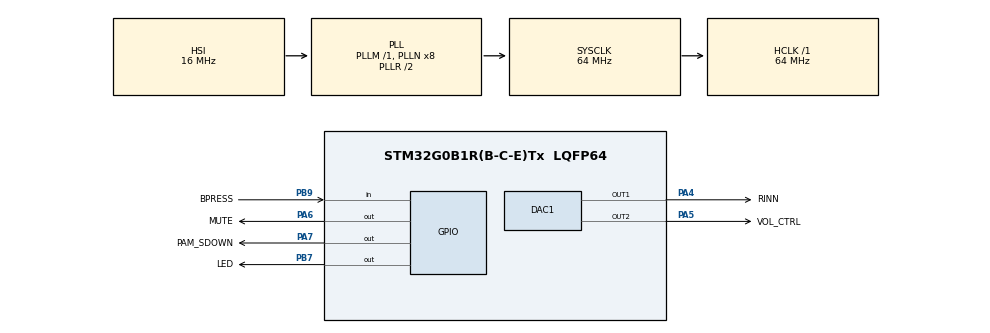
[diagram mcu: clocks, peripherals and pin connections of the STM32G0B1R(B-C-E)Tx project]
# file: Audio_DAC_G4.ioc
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DAC1.DAC_Channel-DAC_OUT1=DAC_CHANNEL_1
DAC1.DAC_Channel-DAC_OUT2=DAC_CHANNEL_2
DAC1.DAC_Trigger-DAC_OUT1=DAC_TRIGGER_T15_TRGO
Dma.DAC1_CH1.0.Direction=DMA_MEMORY_TO_PERIPH
Dma.DAC1_CH1.0.EventEnable=DISABLE
Dma.DAC1_CH1.0.Instance=DMA1_Channel1
Dma.DAC1_CH1.0.MemDataAlignment=DMA_MDATAALIGN_HALFWORD
Dma.DAC1_CH1.0.MemInc=DMA_MINC_ENABLE
Dma.DAC1_CH1.0.Mode=DMA_NORMAL
Dma.DAC1_CH1.0.PeriphDataAlignment=DMA_PDATAALIGN_HALFWORD
Dma.DAC1_CH1.0.PeriphInc=DMA_PINC_DISABLE
Dma.DAC1_CH1.0.Polarity=HAL_DMAMUX_REQ_GEN_RISING
Dma.DAC1_CH1.0.Priority=DMA_PRIORITY_LOW
Dma.DAC1_CH1.0.RequestNumber=1
Dma.DAC1_CH1.0.SignalID=NONE
Dma.DAC1_CH1.0.SyncEnable=DISABLE
Dma.DAC1_CH1.0.SyncPolarity=HAL_DMAMUX_SYNC_NO_EVENT
Dma.DAC1_CH1.0.SyncRequestNumber=1
Dma.DAC1_CH1.0.SyncSignalID=NONE
Dma.Request0=DAC1_CH1
Mcu.Family=STM32G0
Mcu.Name=STM32G0B1R(B-C-E)Tx
Mcu.Package=LQFP64
NVIC.DMA1_Channel1_IRQn=true\:0\:0\:false\:false\:true\:false\:true\:true
NVIC.TIM6_DAC_LPTIM1_IRQn=true\:0\:0\:false\:false\:true\:true\:true\:true
PA13.Mode=Serial_Wire
PA13.Signal=SYS_SWDIO
PA14-BOOT0.Mode=Serial_Wire
PA14-BOOT0.Signal=SYS_SWCLK
PA4.GPIO_Label=RINN
PA4.Signal=COMP_DAC11_group
PA5.GPIO_Label=VOL_CTRL
PA5.Signal=COMP_DAC12_group
PA6.GPIO_Label=MUTE
PA6.Signal=GPIO_Output
PA7.GPIO_Label=PAM_SDOWN
PA7.Signal=GPIO_Output
PB7.GPIO_Label=LED
PB7.Signal=GPIO_Output
PB9.GPIO_Label=BPRESS
PB9.Signal=GPIO_Input
ProjectManager.HeapSize=0x200
ProjectManager.StackSize=0x400
ProjectManager.TargetToolchain=STM32CubeIDE
RCC.ADCFreq_Value=64000000
RCC.AHBFreq_Value=64000000
RCC.CortexFreq_Value=64000000
RCC.EXTERNAL_CLOCK_VALUE=12288000
RCC.HCLKFreq_Value=64000000
RCC.HSE_VALUE=8000000
RCC.HSI48_VALUE=48000000
RCC.HSI_VALUE=16000000
RCC.LSE_VALUE=32768
RCC.PLLQ=RCC_PLLQ_DIV4
RCC.SYSCLKFreq_VALUE=64000000
RCC.SYSCLKSource=RCC_SYSCLKSOURCE_PLLCLK
RCC.USBFreq_Value=48000000
RCC.VCOOutputFreq_Value=128000000
SH.COMP_DAC11_group.0=DAC1_OUT1,DAC_OUT1
SH.COMP_DAC12_group.0=DAC1_OUT2,DAC_OUT2
TIM15.Period=3999
TIM15.Prescaler=1
TIM15.TIM_MasterOutputTrigger=TIM_TRGO_UPDATE
VP_SYS_VS_DBSignals.Mode=DisableDeadBatterySignals
VP_TIM15_VS_ClockSourceINT.Mode=Internal
board=NUCLEO-G0B1RE

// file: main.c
/* USER CODE BEGIN Header */
/**
  ******************************************************************************
  * @file           : main.c
  * @brief          : Main program body
  ******************************************************************************
  * @attention
  *
  * Copyright (c) 2024 STMicroelectronics.
  * All rights reserved.
  *
  * This software is licensed under terms that can be found in the LICENSE file
  * in the root directory of this software component.
  * If no LICENSE file comes with this software, it is provided AS-IS.
  *
  ******************************************************************************
  */
/* USER CODE END Header */
#include "main.h"

/* USER CODE BEGIN Includes */
#include "audio.h"

/* USER CODE END Includes */

DAC_HandleTypeDef hdac1;
DMA_HandleTypeDef hdma_dac1_ch1;

TIM_HandleTypeDef htim15;

/* USER CODE BEGIN PV */

uint32_t volume = 4000; //0=max e 4095=min
/* USER CODE END PV */

void SystemClock_Config(void);
static void MX_GPIO_Init(void);
static void MX_DMA_Init(void);
static void MX_DAC1_Init(void);
static void MX_TIM15_Init(void);

int main(void)
{

  /* MCU Configuration--------------------------------------------------------*/

  /* Reset of all peripherals, Initializes the Flash interface and the Systick. */
  HAL_Init();

  /* Configure the system clock */
  SystemClock_Config();

  /* Initialize all configured peripherals */
  MX_GPIO_Init();
  MX_DMA_Init();
  MX_DAC1_Init();
  MX_TIM15_Init();
  /* USER CODE BEGIN 2 */

  HAL_TIM_Base_Start(&htim15); 		//Audio control timer for 8kHz/125us
  HAL_DAC_Start(&hdac1, DAC_CHANNEL_2); 		//Start DAC volume control
  HAL_DAC_SetValue(&hdac1, DAC_CHANNEL_2, DAC_ALIGN_12B_R, volume);

  HAL_GPIO_WritePin(GPIOA, PAM_SDOWN_Pin, GPIO_PIN_SET); //Full Chip ShutDown Active Low
  HAL_GPIO_WritePin(MUTE_GPIO_Port, MUTE_Pin, GPIO_PIN_RESET);
  /* USER CODE END 2 */

  /* Infinite loop */
  /* USER CODE BEGIN WHILE */
  while (1)
  {
	  if (!HAL_GPIO_ReadPin(BPRESS_GPIO_Port, BPRESS_Pin))
	  {

		  HAL_DAC_SetValue(&hdac1, DAC_CHANNEL_2, DAC_ALIGN_12B_R, volume);
		  HAL_DAC_Start_DMA(&hdac1, DAC_CHANNEL_1, (uint32_t*)arq_audio, tam_total, DAC_ALIGN_12B_R);

		  HAL_GPIO_WritePin(LED_GPIO_Port, LED_Pin, SET);
		  HAL_Delay(2000);
		  HAL_GPIO_WritePin(LED_GPIO_Port, LED_Pin, RESET);
		  HAL_Delay(200);
	  }

    /* USER CODE END WHILE */

  }
}

void SystemClock_Config(void)
{
  RCC_OscInitTypeDef RCC_OscInitStruct = {0};
  RCC_ClkInitTypeDef RCC_ClkInitStruct = {0};

  /** Configure the main internal regulator output voltage
  */
  HAL_PWREx_ControlVoltageScaling(PWR_REGULATOR_VOLTAGE_SCALE1);

  /** Initializes the RCC Oscillators according to the specified parameters
  * in the RCC_OscInitTypeDef structure.
  */
  RCC_OscInitStruct.OscillatorType = RCC_OSCILLATORTYPE_HSI;
  RCC_OscInitStruct.HSIState = RCC_HSI_ON;
  RCC_OscInitStruct.HSIDiv = RCC_HSI_DIV1;
  RCC_OscInitStruct.HSICalibrationValue = RCC_HSICALIBRATION_DEFAULT;
  RCC_OscInitStruct.PLL.PLLState = RCC_PLL_ON;
  RCC_OscInitStruct.PLL.PLLSource = RCC_PLLSOURCE_HSI;
  RCC_OscInitStruct.PLL.PLLM = RCC_PLLM_DIV1;
  RCC_OscInitStruct.PLL.PLLN = 8;
  RCC_OscInitStruct.PLL.PLLP = RCC_PLLP_DIV2;
  RCC_OscInitStruct.PLL.PLLQ = RCC_PLLQ_DIV4;
  RCC_OscInitStruct.PLL.PLLR = RCC_PLLR_DIV2;
  if (HAL_RCC_OscConfig(&RCC_OscInitStruct) != HAL_OK)
  {
    Error_Handler();
  }

  /** Initializes the CPU, AHB and APB buses clocks
  */
  RCC_ClkInitStruct.ClockType = RCC_CLOCKTYPE_HCLK|RCC_CLOCKTYPE_SYSCLK
                              |RCC_CLOCKTYPE_PCLK1;
  RCC_ClkInitStruct.SYSCLKSource = RCC_SYSCLKSOURCE_PLLCLK;
  RCC_ClkInitStruct.AHBCLKDivider = RCC_SYSCLK_DIV1;
  RCC_ClkInitStruct.APB1CLKDivider = RCC_HCLK_DIV1;

  if (HAL_RCC_ClockConfig(&RCC_ClkInitStruct, FLASH_LATENCY_2) != HAL_OK)
  {
    Error_Handler();
  }
}

static void MX_DAC1_Init(void)
{

  DAC_ChannelConfTypeDef sConfig = {0};

  /** DAC Initialization
  */
  hdac1.Instance = DAC1;
  if (HAL_DAC_Init(&hdac1) != HAL_OK)
  {
    Error_Handler();
  }

  /** DAC channel OUT1 config
  */
  sConfig.DAC_SampleAndHold = DAC_SAMPLEANDHOLD_DISABLE;
  sConfig.DAC_Trigger = DAC_TRIGGER_T15_TRGO;
  sConfig.DAC_OutputBuffer = DAC_OUTPUTBUFFER_ENABLE;
  sConfig.DAC_ConnectOnChipPeripheral = DAC_CHIPCONNECT_DISABLE;
  sConfig.DAC_UserTrimming = DAC_TRIMMING_FACTORY;
  if (HAL_DAC_ConfigChannel(&hdac1, &sConfig, DAC_CHANNEL_1) != HAL_OK)
  {
    Error_Handler();
  }

  /** DAC channel OUT2 config
  */
  sConfig.DAC_Trigger = DAC_TRIGGER_NONE;
  if (HAL_DAC_ConfigChannel(&hdac1, &sConfig, DAC_CHANNEL_2) != HAL_OK)
  {
    Error_Handler();
  }

}

static void MX_TIM15_Init(void)
{

  TIM_ClockConfigTypeDef sClockSourceConfig = {0};
  TIM_MasterConfigTypeDef sMasterConfig = {0};

  htim15.Instance = TIM15;
  htim15.Init.Prescaler = 1;
  htim15.Init.CounterMode = TIM_COUNTERMODE_UP;
  htim15.Init.Period = 3999;
  htim15.Init.ClockDivision = TIM_CLOCKDIVISION_DIV1;
  htim15.Init.RepetitionCounter = 0;
  htim15.Init.AutoReloadPreload = TIM_AUTORELOAD_PRELOAD_DISABLE;
  if (HAL_TIM_Base_Init(&htim15) != HAL_OK)
  {
    Error_Handler();
  }
  sClockSourceConfig.ClockSource = TIM_CLOCKSOURCE_INTERNAL;
  if (HAL_TIM_ConfigClockSource(&htim15, &sClockSourceConfig) != HAL_OK)
  {
    Error_Handler();
  }
  sMasterConfig.MasterOutputTrigger = TIM_TRGO_UPDATE;
  sMasterConfig.MasterSlaveMode = TIM_MASTERSLAVEMODE_DISABLE;
  if (HAL_TIMEx_MasterConfigSynchronization(&htim15, &sMasterConfig) != HAL_OK)
  {
    Error_Handler();
  }

}

static void MX_DMA_Init(void)
{

  /* DMA controller clock enable */
  __HAL_RCC_DMA1_CLK_ENABLE();

  /* DMA interrupt init */
  /* DMA1_Channel1_IRQn interrupt configuration */
  HAL_NVIC_SetPriority(DMA1_Channel1_IRQn, 0, 0);
  HAL_NVIC_EnableIRQ(DMA1_Channel1_IRQn);

}

static void MX_GPIO_Init(void)
{
  GPIO_InitTypeDef GPIO_InitStruct = {0};

  /* GPIO Ports Clock Enable */
  __HAL_RCC_GPIOA_CLK_ENABLE();
  __HAL_RCC_GPIOB_CLK_ENABLE();

  /*Configure GPIO pin Output Level */
  HAL_GPIO_WritePin(GPIOA, MUTE_Pin|PAM_SDOWN_Pin, GPIO_PIN_RESET);

  /*Configure GPIO pin Output Level */
  HAL_GPIO_WritePin(LED_GPIO_Port, LED_Pin, GPIO_PIN_RESET);

  /*Configure GPIO pins : MUTE_Pin PAM_SDOWN_Pin */
  GPIO_InitStruct.Pin = MUTE_Pin|PAM_SDOWN_Pin;
  GPIO_InitStruct.Mode = GPIO_MODE_OUTPUT_PP;
  GPIO_InitStruct.Pull = GPIO_NOPULL;
  GPIO_InitStruct.Speed = GPIO_SPEED_FREQ_LOW;
  HAL_GPIO_Init(GPIOA, &GPIO_InitStruct);

  /*Configure GPIO pin : LED_Pin */
  GPIO_InitStruct.Pin = LED_Pin;
  GPIO_InitStruct.Mode = GPIO_MODE_OUTPUT_PP;
  GPIO_InitStruct.Pull = GPIO_NOPULL;
  GPIO_InitStruct.Speed = GPIO_SPEED_FREQ_LOW;
  HAL_GPIO_Init(LED_GPIO_Port, &GPIO_InitStruct);

  /*Configure GPIO pin : BPRESS_Pin */
  GPIO_InitStruct.Pin = BPRESS_Pin;
  GPIO_InitStruct.Mode = GPIO_MODE_INPUT;
  GPIO_InitStruct.Pull = GPIO_NOPULL;
  HAL_GPIO_Init(BPRESS_GPIO_Port, &GPIO_InitStruct);

}

/* USER CODE BEGIN 4 */
//void HAL_DAC_ConvCpltCallbackCh1(DAC_HandleTypeDef *hdac)
//{
//	__NOP();
//}
/* USER CODE END 4 */

void Error_Handler(void)
{
  __disable_irq();
  while (1)
  {
  }
}
